# M031AE_v1 register map
File version: 1.0
Registers are 32-bit, read-write, reset 0x0 unless marked. A register's access mark holds for its fields unless they carry their own. Offsets are from the block's base; [hi:lo] are bit positions; {n}, {i} and the like mark numbered series; 'fields as' and 'values as' point back to an identical list.

## CLK — CLK Register Map
Base 0x40000200
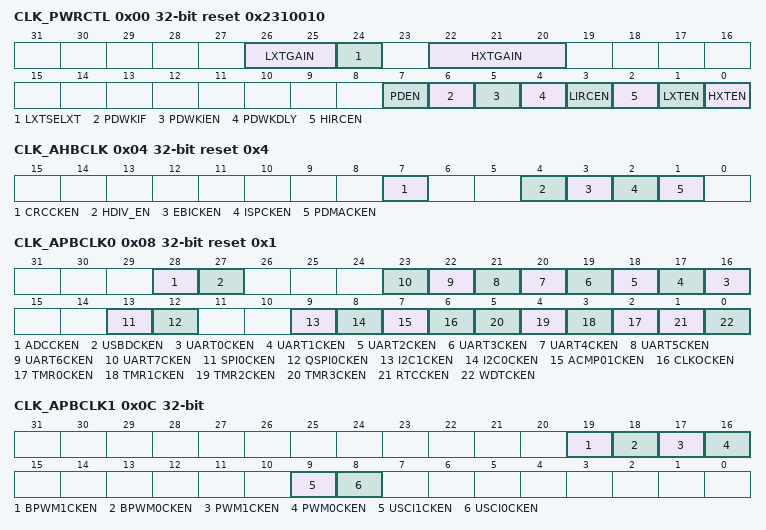
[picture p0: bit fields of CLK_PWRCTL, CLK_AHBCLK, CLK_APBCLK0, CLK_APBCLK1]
0x00 CLK_PWRCTL reset 0x2310010 (reset mask 0xFFFFFFF0) — System Power-down Control Register
  [26:25] LXTGAIN — LXT Gain Control Bit (Write Protect). Note: This bit is write protected. Refer to the SYS_REGLCTL register.
    0=LXT Crystal ESR = 35K, CL=12.5pF; 2=LXT Crystal ESR = 70K, CL=12.5pF
  [24] LXTSELXT — LXT Mode Selection. Note 2: This bit is write protected. Refer to the SYS_REGLCTL register.
    0=LXT work as crystal mode. PF.4 and PF.5 are configured as external low speed crystal (LXT) pins; 1=LXT work as external clock mode. PF.5 is configured as external clock input pin
  [22:20] HXTGAIN — HXT Gain Control Bit (Write Protect). This is a protected register. Please refer to open lock sequence to program it. Gain control is used to enlarge the gain of crystal to make sure crystal work normally. If gain control is enabled, crystal will consume more power than gain control off. Others: Reserved. Note: This bit is write protected. Refer to the SYS_REGLCTL register.
    0=HXT frequency is lower than from 4 MHz; 1=HXT frequency is from 4 MHz to 8 MHz; 2=HXT frequency is from 8 MHz to 12 MHz; 3=HXT frequency is from 12 MHz to 16 MHz; 4=HXT frequency is from 16 MHz to 24 MHz; 7=HXT frequency is from 24 MHz to 32 MHz
  [7] PDEN — System Power-down Enable (Write Protect). When this bit is set to 1, Power-down mode is enabled and chip keeps active till the CPU sleep mode is also active and then the chip enters Power-down mode. When chip wakes up from Power-down mode, this bit is auto cleared. Users need to set this bit again for next Power-down. In Power-down mode, HXT and the HIRC will be disabled in this mode, but LXT and LIRC are not controlled by Power-down mode. If user disable LIRC before entering power-down mode, this bit should be set after LIRC disabled 50us. In Power-down mode, the PLL and system clock are disabled, and ignored the clock source selection. The clocks of peripheral are not controlled by Power-down mode, if the peripheral clock source is from LXT or LIRC. Note: This bit is write protected. Refer to the SYS_REGLCTL register.
    0=Chip operating normally or chip in idle mode because of WFI command; 1=Chip enters Power-down mode instant or wait CPU sleep command WFI
  [6] PDWKIF — Power-down Mode Wake-up Interrupt Status. Set by 'Power-down wake-up event', it indicates that resume from Power-down mode' The flag is set if any wake-up source is occurred. Refer Power Modes and Wake-up Sources chapter. Note 1: Write 1 to clear the bit to 0. Note 2: This bit works only if PDWKIEN (CLK_PWRCTL[5]) set to 1.
  [5] PDWKIEN — Power-down Mode Wake-up Interrupt Enable Bit (Write Protect). Note 1: The interrupt will occur when both PDWKIF and PDWKIEN are high. Note 2: This bit is write protected. Refer to the SYS_REGLCTL register.
    0=Power-down mode wake-up interrupt Disabled; 1=Power-down mode wake-up interrupt Enabled
  [4] PDWKDLY — Enable the Wake-up Delay Counter (Write Protect). When the chip wakes up from Power-down mode, the clock control will delay certain clock cycles to wait system clock stable. The delayed clock cycle is 4096 clock cycles when chip works at external high speed crystal oscillator (HXT), and 512 clock cycles when chip works at internal high speed RC oscillator (HIRC). Note: This bit is write protected. Refer to the SYS_REGLCTL register.
    0=Clock cycles delay Disabled; 1=Clock cycles delay Enabled
  [3] LIRCEN — LIRC Enable Bit (Write Protect). Note: This bit is write protected. Refer to the SYS_REGLCTL register.
    0=Internal low speed RC oscillator (LIRC) Disabled; 1=Internal low speed RC oscillator (LIRC) Enabled
  [2] HIRCEN — HIRC Enable Bit (Write Protect). Note: This bit is write protected. Refer to the SYS_REGLCTL register.
    0=Internal high speed RC oscillator (HIRC) Disabled; 1=Internal high speed RC oscillator (HIRC) Enabled
  [1] LXTEN — LXT Enable Bit (Write Protect). Note1 : Note 2: This bit is write protected. Refer to the SYS_REGLCTL register.
    0=External low speed crystal (LXT) Disabled; 1=External low speed crystal (LXT) Enabled
  [0] HXTEN — HXT Enable Bit (Write Protect). Note1 : reset by power on reset. Note 2: This bit is write protected. Refer to the SYS_REGLCTL register.
    0=Eexternal high speed crystal (HXT) Disabled; 1=External high speed crystal (HXT) Enabled
0x04 CLK_AHBCLK reset 0x4 — AHB Devices Clock Enable Control Register
  [7] CRCCKEN — CRC Generator Controller Clock Enable Bit
    0=CRC peripheral clock Disabled; 1=CRC peripheral clock Enabled
  [4] HDIV_EN — Divider Controller Clock Enable Control
    0=Divider controller peripheral clock Disabled; 1=Divider controller peripheral clock Enabled
  [3] EBICKEN — EBI Controller Clock Enable Bit
    0=EBI peripheral clock Disabled; 1=EBI peripheral clock Enabled
  [2] ISPCKEN — Flash ISP Controller Clock Enable Bit
    0=Flash ISP peripheral clock Disabled; 1=Flash ISP peripheral clock Enabled
  [1] PDMACKEN — PDMA Controller Clock Enable Bit
    0=PDMA peripheral clock Disabled; 1=PDMA peripheral clock Enabled
0x08 CLK_APBCLK0 reset 0x1 — APB Devices Clock Enable Control Register 0
  [28] ADCCKEN — Analog-digital-converter (ADC) Clock Enable Bit
    0=ADC clock Disabled; 1=ADC clock Enabled
  [27] USBDCKEN — USB Device Clock Enable Bit
    0=USB Device clock Disabled; 1=USB Device clock Enabled
  [n+16] UART{n}CKEN (n=0..7) — UART{n} Clock Enable Bit
    0=UART{n} clock Disabled; 1=UART{n} clock Enabled
  [13] SPI0CKEN — SPI0 Clock Enable Bit
    0=SPI0 clock Disabled; 1=SPI0 clock Enabled
  [12] QSPI0CKEN — QSPI0 Clock Enable Bit
    0=QSPI0 clock Disabled; 1=QSPI0 clock Enabled
  [9] I2C1CKEN — I2C1 Clock Enable Bit
    0=I2C1 clock Disabled; 1=I2C1 clock Enabled
  [8] I2C0CKEN — I2C0 Clock Enable Bit
    0=I2C0 clock Disabled; 1=I2C0 clock Enabled
  [7] ACMP01CKEN — Analog Comparator 0/1 Clock Enable Bit
    0=Analog comparator 0/1 clock Disabled; 1=Analog comparator 0/1 clock Enabled
  [6] CLKOCKEN — CLKO Clock Enable Bit
    0=CLKO clock Disabled; 1=CLKO clock Enabled
  [n+2] TMR{n}CKEN (n=0..3) — Timer{n} Clock Enable Bit
    0=Timer{n} clock Disabled; 1=Timer{n} clock Enabled
  [1] RTCCKEN — RTC Clock Enable Bit
    0=RTC clock Disabled; 1=RTC clock Enabled
  [0] WDTCKEN — Watchdog Timer Clock Enable Bit (Write Protect). Note: This bit is write protected. Refer to the SYS_REGLCTL register. Note: This bit is reset by power on reset, Watchdog reset or software chip reset.
    0=Watchdog timer clock Disabled; 1=Watchdog timer clock Enabled
0x0C CLK_APBCLK1 — APB Devices Clock Enable Control Register 1
  [19] BPWM1CKEN — BPWM1 Clock Enable Bit
    0=BPWM1 clock Disabled; 1=BPWM1 clock Enabled
  [18] BPWM0CKEN — BPWM0 Clock Enable Bit
    0=BPWM0 clock Disabled; 1=BPWM0 clock Enabled
  [17] PWM1CKEN — PWM1 Clock Enable Bit
    0=PWM1 clock Disabled; 1=PWM1 clock Enabled
  [16] PWM0CKEN — PWM0 Clock Enable Bit
    0=PWM0 clock Disabled; 1=PWM0 clock Enabled
  [9] USCI1CKEN — USCI1 Clock Enable Bit
    0=USCI1 clock Disabled; 1=USCI1 clock Enabled
  [8] USCI0CKEN — USCI0 Clock Enable Bit
    0=USCI0 clock Disabled; 1=USCI0 clock Enabled
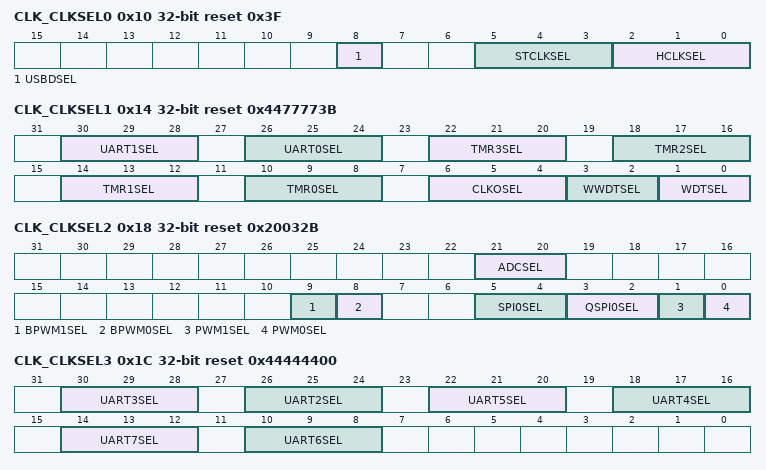
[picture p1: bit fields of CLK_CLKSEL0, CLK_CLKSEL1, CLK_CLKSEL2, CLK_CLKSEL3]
0x10 CLK_CLKSEL0 reset 0x3F — Clock Source Select Control Register 0
  [8] USBDSEL — USB Device Clock Source Selection (Write Protect). These bits are protected bit. It means programming this bit needs to write '59h', '16h', '88h' to address 0x4000_0100 to disable register protection. Refer to the register REGWRPROT at address GCR_BA+0x100. Note: If PLL is not supported, clock source of selection '1' will be changed to HIRC. Please refer to section 3.2 NuMicro M031/M032 Series Selection Guide for detailed information.
    0=Clock source from HIRC; 1=Clock source from PLL divided
  [5:3] STCLKSEL — Cortex-M0 SysTick Clock Source Selection (Write Protect). Note: This bit is write protected. Refer to the SYS_REGLCTL register. Note: If LXT or HXT is not supported, clock source of selection '000', '001', or '010' will be stopped. Please refer to section 3.2 NuMicro M031/M032 Series Selection Guide for detailed information.
    0=Clock source from HXT; 1=Clock source from LXT; 2=Clock source from HXT/2; 3=Clock source from HCLK/2; 7=Clock source from HIRC/2
  [2:0] HCLKSEL — HCLK Clock Source Selection (Write Protect). Before clock switching, the related clock sources (both pre-select and new-select) must be turned on. Note: This bit is write protected. Refer to the SYS_REGLCTL register. Note : reset by power on reset. Note: If PLL is not supported, clock source of selection '010' will be changed to HIRC. Note: If LXT or HXT is not supported, clock source of selection '000'or '001' will be kept previous clock selection. Please refer to section 3.2 NuMicro M031/M032 Series Selection Guide for detailed information.
    0=Clock source from HXT; 1=Clock source from LXT; 2=Clock source from PLL; 3=Clock source from LIRC; 7=Clock source from HIRC
0x14 CLK_CLKSEL1 reset 0x4477773B — Clock Source Select Control Register 1
  [30:28] UART1SEL — UART1 Clock Source Selection. Note: If PLL is not supported, clock source of selection '001' will be changed to PCLK1. Note: If LXT or HXT is not supported, clock source of selection '000' or '010' will be stopped. Please refer to section 3.2 NuMicro M031/M032 Series Selection Guide for detailed information.
    0=Clock source from external high speed crystal oscillator (HXT); 1=Clock source from PLL; 2=Clock source from external low speed crystal oscillator (LXT); 3=Clock source from internal high speed RC oscillator (HIRC); 4=Clock source from PCLK1; 5=Clock source from internal low speed RC oscillator (LIRC)
  [26:24] UART0SEL — UART0 Clock Source Selection. Note: If PLL is not supported, clock source of selection '001' will be changed to PCLK0. Note: If LXT or HXT is not supported, clock source of selection '000' or '010' will be stopped. Please refer to section 3.2 NuMicro M031/M032 Series Selection Guide for detailed information.
    0=Clock source from external high speed crystal oscillator (HXT); 1=Clock source from PLL; 2=Clock source from external low speed crystal oscillator (LXT); 3=Clock source from internal high speed RC oscillator (HIRC); 4=Clock source from PCLK0; 5=Clock source from internal low speed RC oscillator (LIRC)
  [22:20] TMR3SEL — TIMER3 Clock Source Selection. Note: If LXT or HXT is not supported, clock source of selection '000' or '001' will be stopped. Please refer to section 3.2 NuMicro M031/M032 Series Selection Guide for detailed information.
    0=Clock source from external high speed crystal oscillator (HXT); 1=Clock source from external low speed crystal oscillator (LXT); 2=Clock source from PCLK1; 3=Clock source from external clock TM3 pin; 5=Clock source from internal low speed RC oscillator (LIRC); 7=Clock source from internal high speed RC oscillator (HIRC)
  [18:16] TMR2SEL — TIMER2 Clock Source Selection. Note: If LXT or HXT is not supported, clock source of selection '000' or '001' will be stopped. Please refer to section 3.2 NuMicro M031/M032 Series Selection Guide for detailed information.
    0=Clock source from external high speed crystal oscillator (HXT); 1=Clock source from external low speed crystal oscillator (LXT); 2=Clock source from PCLK1; 3=Clock source from external clock TM2 pin; 5=Clock source from internal low speed RC oscillator (LIRC); 7=Clock source from internal high speed RC oscillator (HIRC)
  [14:12] TMR1SEL — TIMER1 Clock Source Selection. Note: If LXT or HXT is not supported, clock source of selection '000' or '001' will be stopped. Please refer to section 3.2 NuMicro M031/M032 Series Selection Guide for detailed information.
    0=Clock source from external high speed crystal oscillator (HXT); 1=Clock source from external low speed crystal oscillator (LXT); 2=Clock source from PCLK0; 3=Clock source from external clock TM1 pin; 5=Clock source from internal low speed RC oscillator (LIRC); 7=Clock source from internal high speed RC oscillator (HIRC)
  [10:8] TMR0SEL — TIMER0 Clock Source Selection. Note: If LXT or HXT is not supported, clock source of selection '000' or '001' will be stopped. Please refer to section 3.2 NuMicro M031/M032 Series Selection Guide for detailed information.
    0=Clock source from external high speed crystal oscillator (HXT); 1=Clock source from external low speed crystal oscillator (LXT); 2=Clock source from PCLK0; 3=Clock source from external clock TM0 pin; 5=Clock source from internal low speed RC oscillator (LIRC); 7=Clock source from internal high speed RC oscillator (HIRC)
  [6:4] CLKOSEL — Clock Divider Clock Source Selection. Note: If PLL is not supported, clock source of selection '110' will be changed to HIRC. Note: If LXT or HXT is not supported, clock source of selection '000' or '001' will be stopped. Please refer to section 3.2 NuMicro M031/M032 Series Selection Guide for detailed information.
    0=Clock source from external high speed crystal oscillator (HXT); 1=Clock source from external low speed crystal oscillator (LXT); 2=Clock source from HCLK; 3=Clock source from internal high speed RC oscillator (HIRC); 4=Clock source from internal low speed RC oscillator (LIRC); 5=Clock source from internal high speed RC oscillator (HIRC); 6=Clock source from PLL
  [3:2] WWDTSEL — Window Watchdog Timer Clock Source Selection (Write Protect)
    2=Clock source from HCLK/2048; 3=Clock source from internal low speed RC oscillator (LIRC)
  [1:0] WDTSEL — Watchdog Timer Clock Source Selection (Write Protect). Note: This bit is write protected. Refer to the SYS_REGLCTL register. 2. Will be forced to 11 when CONFIG0[31], CONFIG0[4], CONFIG0[3] are all ones. Note: If LXT is not supported, clock source of selection '01' will be stopped. Please refer to section 3.2 NuMicro M031/M032 Series Selection Guide for detailed information.
    1=Clock source from external low speed crystal oscillator (LXT); 2=Clock source from HCLK/2048; 3=Clock source from internal low speed RC oscillator (LIRC)
0x18 CLK_CLKSEL2 reset 0x20032B — Clock Source Select Control Register 2
  [21:20] ADCSEL — ADC Clock Source Selection. Note: If PLL is not supported, clock source of selection '01' will be changed to PCLK1. Note: If HXT is not supported, clock source of selection '00' will be stopped. Please refer to section 3.2 NuMicro M031/M032 Series Selection Guide for detailed information.
    0=Clock source from external high speed crystal oscillator (HXT) clock; 1=Clock source from PLL; 2=Clock source from PCLK1; 3=Clock source from internal high speed RC oscillator (HIRC) clock
  [9] BPWM1SEL — BPWM1 Clock Source Selection. The peripheral clock source of BPWM1 is defined by BPWM1SEL. Note: If PLL is not supported, clock source of selection '0' will be changed to PCLK1. Please refer to section 3.2 NuMicro M031/M032 Series Selection Guide for detailed information.
    0=Clock source from PLL; 1=Clock source from PCLK1
  [8] BPWM0SEL — BPWM0 Clock Source Selection. The peripheral clock source of BPWM0 is defined by BPWM0SEL. Note: If PLL is not supported, clock source of selection '0' will be changed to PCLK0. Please refer to section 3.2 NuMicro M031/M032 Series Selection Guide for detailed information.
    0=Clock source from PLL; 1=Clock source from PCLK0
  [5:4] SPI0SEL — SPI0 Clock Source Selection. Note: If PLL is not supported, clock source of selection '01' will be changed to PCLK1. Note: If HXT is not supported, clock source of selection '00' will be stopped. Please refer to section 3.2 NuMicro M031/M032 Series Selection Guide for detailed information.
    0=Clock source from external high speed crystal oscillator (HXT); 1=Clock source from PLL; 2=Clock source from PCLK1; 3=Clock source from internal high speed RC oscillator (HIRC)
  [3:2] QSPI0SEL — QSPI0 Clock Source Selection. Note: If PLL is not supported, clock source of selection '01' will be changed to PCLK0. Note: If HXT is not supported, clock source of selection '00' will be stopped. Please refer to section 3.2 NuMicro M031/M032 Series Selection Guide for detailed information.
    0=Clock source from external high speed crystal oscillator (HXT); 1=Clock source from PLL; 2=Clock source from PCLK0; 3=Clock source from internal high speed RC oscillator (HIRC)
  [1] PWM1SEL — PWM1 Clock Source Selection. The peripheral clock source of PWM1 is defined by PWM1SEL. Note: If PLL is not supported, clock source of selection '0' will be changed to PCLK1. Please refer to section 3.2 NuMicro M031/M032 Series Selection Guide for detailed information.
    0=Clock source from PLL; 1=Clock source from PCLK1
  [0] PWM0SEL — PWM0 Clock Source Selection. The peripheral clock source of PWM0 is defined by PWM0SEL. Note: If PLL is not supported, clock source of selection '0' will be changed to PCLK0. Please refer to section 3.2 NuMicro M031/M032 Series Selection Guide for detailed information.
    0=Clock source from PLL; 1=Clock source from PCLK0
0x1C CLK_CLKSEL3 reset 0x44444400 — Clock Source Select Control Register 3
  [30:28] UART3SEL — UART3 Clock Source Selection. Note: If PLL is not supported, clock source of selection '001' will be changed to PCLK1. Note: If LXT or HXT is not supported, clock source of selection '000' or '010' will be stopped. Please refer to section 3.2 NuMicro M031/M032 Series Selection Guide for detailed information.
    values as CLK_CLKSEL1.UART1SEL
  [26:24] UART2SEL — UART2 Clock Source Selection. Note: If PLL is not supported, clock source of selection '001' will be changed to PCLK0. Note: If LXT or HXT is not supported, clock source of selection '000' or '010' will be stopped. Please refer to section 3.2 NuMicro M031/M032 Series Selection Guide for detailed information.
    values as CLK_CLKSEL1.UART0SEL
  [22:20] UART5SEL — UART5 Clock Source Selection. Note: If PLL is not supported, clock source of selection '001' will be changed to PCLK1. Note: If LXT or HXT is not supported, clock source of selection '000' or '010' will be stopped. Please refer to section 3.2 NuMicro M031/M032 Series Selection Guide for detailed information.
    values as CLK_CLKSEL1.UART1SEL
  [18:16] UART4SEL — UART4 Clock Source Selection. Note: If PLL is not supported, clock source of selection '001' will be changed to PCLK0. Note: If LXT or HXT is not supported, clock source of selection '000' or '010' will be stopped. Please refer to section 3.2 NuMicro M031/M032 Series Selection Guide for detailed information.
    values as CLK_CLKSEL1.UART0SEL
  [14:12] UART7SEL — UART7 Clock Source Selection. Note: If PLL is not supported, clock source of selection '001' will be changed to PCLK1. Note: If LXT or HXT is not supported, clock source of selection '000' or '010' will be stopped. Please refer to section 3.2 NuMicro M031/M032 Series Selection Guide for detailed information.
    values as CLK_CLKSEL1.UART1SEL
  [10:8] UART6SEL — UART6 Clock Source Selection. Note: If PLL is not supported, clock source of selection '001' will be changed to PCLK0. Note: If LXT or HXT is not supported, clock source of selection '000' or '010' will be stopped. Please refer to section 3.2 NuMicro M031/M032 Series Selection Guide for detailed information.
    values as CLK_CLKSEL1.UART0SEL
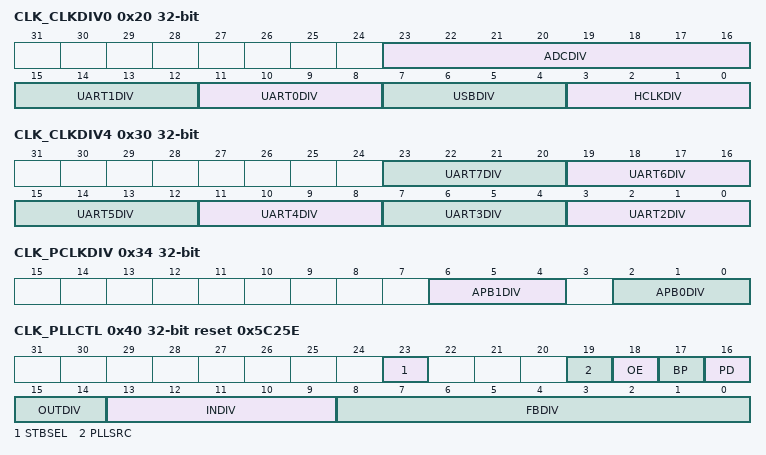
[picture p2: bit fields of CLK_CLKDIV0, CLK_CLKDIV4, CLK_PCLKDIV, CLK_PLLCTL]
0x20 CLK_CLKDIV0 — Clock Divider Number Register 0
  [23:16] ADCDIV — ADC Clock Divide Number From ADC Clock Source
  [15:12] UART1DIV — UART1 Clock Divide Number From UART1 Clock Source
  [11:8] UART0DIV — UART0 Clock Divide Number From UART0 Clock Source
  [7:4] USBDIV — USB Clock Divide Number From PLL Clock
  [3:0] HCLKDIV — HCLK Clock Divide Number From HCLK Clock Source
0x30 CLK_CLKDIV4 — Clock Divider Number Register 4
  [4n-5:4n-8] UART{n}DIV (n=2..7) — UART{n} Clock Divide Number From UART{n} Clock Source
0x34 CLK_PCLKDIV — APB Clock Divider Register
  [6:4] APB1DIV — APB1 Clock DIvider. APB1 clock can be divided from HCLK. Others: Reserved.
  [2:0] APB0DIV — APB0 Clock DIvider. APB0 clock can be divided from HCLK. Others: Reserved.
0x40 CLK_PLLCTL reset 0x5C25E — PLL Control Register
  [23] STBSEL — PLL Stable Counter Selection (Write Protect). Note: This bit is write protected. Refer to the SYS_REGLCTL register.
    0=PLL stable time is 6144 PLL source clock (suitable for source clock is equal to or less than 12 MHz ); 1=PLL stable time is 16128 PLL source clock (suitable for source clock is larger than 12 MHz)
  [19] PLLSRC — PLL Source Clock Selection (Write Protect). Note: This bit is write protected. Refer to the SYS_REGLCTL register.
    0=PLL source clock from external high-speed crystal oscillator (HXT); 1=PLL source clock from 48 MHz internal high-speed oscillator (HIRC/4)
  [18] OE — PLL OE (FOUT Enable) Pin Control (Write Protect). Note: This bit is write protected. Refer to the SYS_REGLCTL register.
    0=PLL FOUT Enabled; 1=PLL FOUT is fixed low
  [17] BP — PLL Bypass Control (Write Protect). Note: This bit is write protected. Refer to the SYS_REGLCTL register.
    0=PLL is in normal mode (default); 1=PLL clock output is same as PLL input clock FIN
  [16] PD — Power-down Mode (Write Protect). If set the PDEN bit to 1 in CLK_PWRCTL register, the PLL will enter Power-down mode, too. Note: This bit is write protected. Refer to the SYS_REGLCTL register.
    0=PLL is in normal mode; 1=PLL is in Power-down mode (default)
  [15:14] OUTDIV — PLL Output Divider Control (Write Protect). Refer to the formulas below the table. Note: This bit is write protected. Refer to the SYS_REGLCTL register.
  [13:9] INDIV — PLL Input Divider Control (Write Protect). Refer to the formulas below the table. Note: This bit is write protected. Refer to the SYS_REGLCTL register.
  [8:0] FBDIV — PLL Feedback Divider Control (Write Protect). Refer to the formulas below the table. Note: This bit is write protected. Refer to the SYS_REGLCTL register.
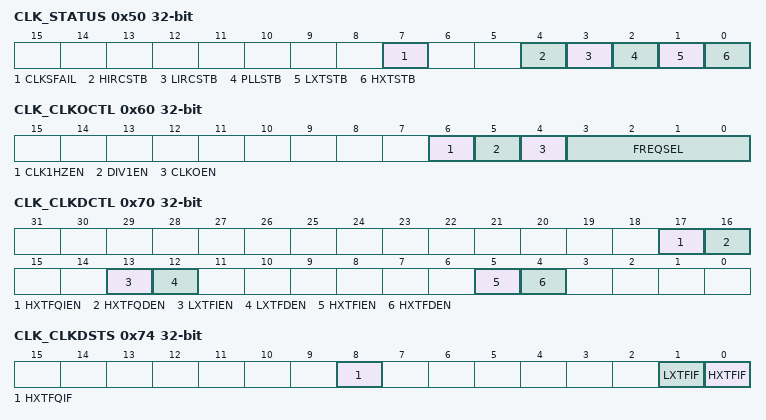
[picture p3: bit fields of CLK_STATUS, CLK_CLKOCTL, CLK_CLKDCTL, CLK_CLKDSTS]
0x50 CLK_STATUS ro (reset mask 0xFFFFFF00) — Clock Status Monitor Register
  [7] CLKSFAIL — Clock Switching Fail Flag (Read Only). This bit is updated when software switches system clock source. If switch target clock is stable, this bit will be set to 0. If switch target clock is not stable, this bit will be set to 1. Note: Write 1 to clear the bit to 0.
    0=Clock switching success; 1=Clock switching failure
  [4] HIRCSTB — HIRC Clock Source Stable Flag (Read Only)
    0=Internal high speed RC oscillator (HIRC) clock is not stable or disabled; 1=Internal high speed RC oscillator (HIRC) clock is stable and enabled
  [3] LIRCSTB — LIRC Clock Source Stable Flag (Read Only)
    0=Internal low speed RC oscillator (LIRC) clock is not stable or disabled; 1=Internal low speed RC oscillator (LIRC) clock is stable and enabled
  [2] PLLSTB — Internal PLL Clock Source Stable Flag (Read Only). Note: If PLL is not supported, this bit field will be invalid. Please refer to section 3.2 NuMicro M031/M032 Series Selection Guide for detailed information.
    0=Internal PLL clock is not stable or disabled; 1=Internal PLL clock is stable and enabled
  [1] LXTSTB — LXT Clock Source Stable Flag (Read Only). Note: If LXT is not supported, this bit field will be invalid. Please refer to section 3.2 NuMicro M031/M032 Series Selection Guide for detailed information.
    0=External low speed crystal oscillator (LXT) clock is not stable or disabled; 1=External low speed crystal oscillator (LXT) clock is stabled and enabled
  [0] HXTSTB — HXT Clock Source Stable Flag (Read Only). Note: If HXT is not supported, this bit field will be invalid. Please refer to section 3.2 NuMicro M031/M032 Series Selection Guide for detailed information.
    0=External high speed crystal oscillator (HXT) clock is not stable or disabled; 1=External high speed crystal oscillator (HXT) clock is stable and enabled
0x60 CLK_CLKOCTL — Clock Output Control Register
  [6] CLK1HZEN — Clock Output 1Hz Enable Bit
    0=1 Hz clock output for 32.768 kHz frequency compensation Disabled; 1=1 Hz clock output for 32.768 kHz frequency compensation Enabled
  [5] DIV1EN — Clock Output Divide One Enable Bit
    0=Clock Output will output clock with source frequency divided by FREQSEL; 1=Clock Output will output clock with source frequency
  [4] CLKOEN — Clock Output Enable Bit
    0=Clock Output function Disabled; 1=Clock Output function Enabled
  [3:0] FREQSEL — Clock Output Frequency Selection. The formula of output frequency is. Fin is the input clock frequency. Fout is the frequency of divider output clock. N is the 4-bit value of FREQSEL[3:0].
0x70 CLK_CLKDCTL — Clock Fail Detector Control Register
  [17] HXTFQIEN — HXT Clock Frequency Range Detector Interrupt Enable Bit
    0=External high speed crystal oscillator (HXT) clock frequency range detector fail interrupt Disabled; 1=External high speed crystal oscillator (HXT) clock frequency range detector fail interrupt Enabled
  [16] HXTFQDEN — HXT Clock Frequency Range Detector Enable Bit
    0=External high speed crystal oscillator (HXT) clock frequency range detector Disabled; 1=External high speed crystal oscillator (HXT) clock frequency range detector Enabled
  [13] LXTFIEN — LXT Clock Fail Interrupt Enable Bit
    0=External low speed crystal oscillator (LXT) clock fail interrupt Disabled; 1=External low speed crystal oscillator (LXT) clock fail interrupt Enabled
  [12] LXTFDEN — LXT Clock Fail Detector Enable Bit
    0=External low speed crystal oscillator (LXT) clock fail detector Disabled; 1=External low speed crystal oscillator (LXT) clock fail detector Enabled
  [5] HXTFIEN — HXT Clock Fail Interrupt Enable Bit
    0=External high speed crystal oscillator (HXT) clock fail interrupt Disabled; 1=External high speed crystal oscillator (HXT) clock fail interrupt Enabled
  [4] HXTFDEN — HXT Clock Fail Detector Enable Bit
    0=External high speed crystal oscillator (HXT) clock fail detector Disabled; 1=External high speed crystal oscillator (HXT) clock fail detector Enabled
0x74 CLK_CLKDSTS — Clock Fail Detector Status Register
  [8] HXTFQIF — HXT Clock Frequency Range Detector Interrupt Flag (Write Protect). Note: Write 1 to clear the bit to 0.
    0=External high speed crystal oscillator (HXT) clock frequency is normal; 1=External high speed crystal oscillator (HXT) clock frequency is abnormal
  [1] LXTFIF — LXT Clock Fail Interrupt Flag (Write Protect). Note: Write 1 to clear the bit to 0.
    0=External low speed crystal oscillator (LXT) clock is normal; 1=External low speed crystal oscillator (LXT) stops
  [0] HXTFIF — HXT Clock Fail Interrupt Flag (Write Protect). Note: Write 1 to clear the bit to 0.
    0=External high speed crystal oscillator (HXT) clock is normal; 1=External high speed crystal oscillator (HXT) clock stops
0x78 CLK_CDUPB — Clock Frequency Range Detector Upper Boundary Register
  [9:0] UPERBD — HXT Clock Frequency Range Detector Upper Boundary Value. The bits define the maximum value of frequency range detector window. When HXT frequency is higher than this maximum frequency value, the HXT Clock Frequency Range Detector Interrupt Flag will be set to 1.
0x7C CLK_CDLOWB — Clock Frequency Range Detector Lower Boundary Register
  [9:0] LOWERBD — HXT Clock Frequency Range Detector Lower Boundary Value. The bits define the minimum value of frequency range detector window. When HXT frequency lower than this minimum frequency value, the HXT Clock Frequency Range Detector Interrupt Flag will set to 1.
0x80 CLK_LDOCTL — LDO Control Register
0xB4 CLK_HXTFSEL — HXT Filter Select Control Register
  [0] HXTFSEL — HXT Filter Select. Note: This bit should not be changed during HXT running.
    0=HXT frequency is greater than12 MHz; 1=HXT frequency is less than or equal to 12 MHz
